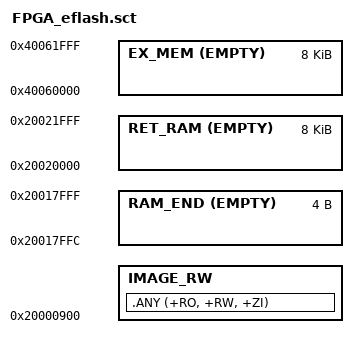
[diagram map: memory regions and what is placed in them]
; *************************************************************
; *** Scatter-Loading Description File generated by uVision ***
; *************************************************************

SOC 0x10000000 0x30000  ; 192KB
{
    STARTUP + 0
    {
        *(VECTOR_IN_EFLASH, +First)
        *(InRoot$$Sections)
    }

    IMAGE_RO + 0
    {
        * (+RO)
    }

    IMAGE_RW 0x20000900      ; fixed address after BootROM BLE_ZI
    {
        *(RO_IN_SYS_RAM)
        * (+RW)
    }

    IMAGE_ZI + 0
    {
        * (+ZI)
    }

    RAM_START + 0
    {
        .ANY (+RO, +RW, +ZI)
    }

    RAM_END 0x20018000 EMPTY -0x4
    {

    }

    RET_RAM 0x20020000 EMPTY 0x2000 ; Retention memory
    {

    }

    EX_MEM 0x40060000 EMPTY 0x2000 ; Exchange memory
    {

    }
}

